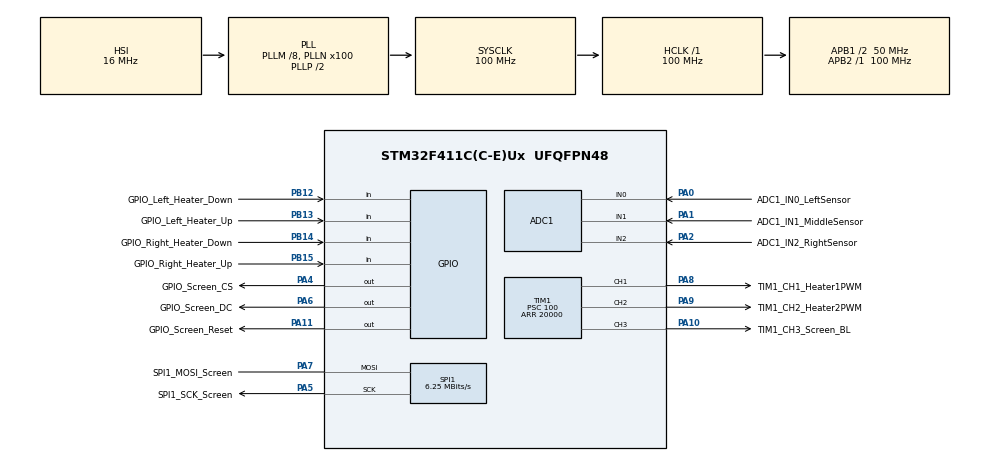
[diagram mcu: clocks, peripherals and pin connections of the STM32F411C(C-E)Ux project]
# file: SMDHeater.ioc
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ADC1.Channel-0\#ChannelRegularConversion=ADC_CHANNEL_0
ADC1.Channel-1\#ChannelRegularConversion=ADC_CHANNEL_1
ADC1.Channel-2\#ChannelRegularConversion=ADC_CHANNEL_2
ADC1.ContinuousConvMode=ENABLE
ADC1.DMAContinuousRequests=ENABLE
ADC1.NbrOfConversion=3
ADC1.NbrOfConversionFlag=1
ADC1.Rank-0\#ChannelRegularConversion=1
ADC1.Rank-1\#ChannelRegularConversion=2
ADC1.Rank-2\#ChannelRegularConversion=3
ADC1.SamplingTime-0\#ChannelRegularConversion=ADC_SAMPLETIME_84CYCLES
ADC1.SamplingTime-1\#ChannelRegularConversion=ADC_SAMPLETIME_84CYCLES
ADC1.SamplingTime-2\#ChannelRegularConversion=ADC_SAMPLETIME_84CYCLES
ADC1.master=1
Dma.ADC1.0.Direction=DMA_PERIPH_TO_MEMORY
Dma.ADC1.0.FIFOMode=DMA_FIFOMODE_DISABLE
Dma.ADC1.0.Instance=DMA2_Stream0
Dma.ADC1.0.MemDataAlignment=DMA_MDATAALIGN_WORD
Dma.ADC1.0.MemInc=DMA_MINC_ENABLE
Dma.ADC1.0.Mode=DMA_CIRCULAR
Dma.ADC1.0.PeriphDataAlignment=DMA_PDATAALIGN_WORD
Dma.ADC1.0.PeriphInc=DMA_PINC_DISABLE
Dma.ADC1.0.Priority=DMA_PRIORITY_LOW
Dma.Request0=ADC1
Mcu.Family=STM32F4
Mcu.Name=STM32F411C(C-E)Ux
Mcu.Package=UFQFPN48
NVIC.ADC_IRQn=true\:0\:0\:false\:false\:true\:true\:true\:true
NVIC.DMA2_Stream0_IRQn=true\:0\:0\:false\:false\:true\:false\:true\:true
NVIC.PriorityGroup=NVIC_PRIORITYGROUP_4
PA0-WKUP.GPIO_Label=ADC1_IN0_LeftSensor
PA0-WKUP.Signal=ADCx_IN0
PA1.GPIO_Label=ADC1_IN1_MiddleSensor
PA1.Signal=ADCx_IN1
PA10.GPIO_Label=TIM1_CH3_Screen_BL
PA10.Signal=S_TIM1_CH3
PA11.GPIO_Label=GPIO_Screen_Reset
PA11.Signal=GPIO_Output
PA13.Mode=Serial_Wire
PA13.Signal=SYS_JTMS-SWDIO
PA14.Mode=Serial_Wire
PA14.Signal=SYS_JTCK-SWCLK
PA2.GPIO_Label=ADC1_IN2_RightSensor
PA2.Signal=ADCx_IN2
PA4.GPIO_Label=GPIO_Screen_CS
PA4.Signal=GPIO_Output
PA5.GPIO_Label=SPI1_SCK_Screen
PA5.Mode=Simplex_Bidirectional_Master
PA5.Signal=SPI1_SCK
PA6.GPIO_Label=GPIO_Screen_DC
PA6.Signal=GPIO_Output
PA7.GPIO_Label=SPI1_MOSI_Screen
PA7.Mode=Simplex_Bidirectional_Master
PA7.Signal=SPI1_MOSI
PA8.GPIO_Label=TIM1_CH1_Heater1PWM
PA8.Signal=S_TIM1_CH1
PA9.GPIO_Label=TIM1_CH2_Heater2PWM
PA9.Signal=S_TIM1_CH2
PB12.GPIO_Label=GPIO_Left_Heater_Down
PB12.GPIO_PuPd=GPIO_PULLUP
PB12.Signal=GPIO_Input
PB13.GPIO_Label=GPIO_Left_Heater_Up
PB13.GPIO_PuPd=GPIO_PULLUP
PB13.Signal=GPIO_Input
PB14.GPIO_Label=GPIO_Right_Heater_Down
PB14.GPIO_PuPd=GPIO_PULLUP
PB14.Signal=GPIO_Input
PB15.GPIO_Label=GPIO_Right_Heater_Up
PB15.GPIO_PuPd=GPIO_PULLUP
PB15.Signal=GPIO_Input
PH0\ -\ OSC_IN.Mode=HSE-External-Oscillator
PH0\ -\ OSC_IN.Signal=RCC_OSC_IN
PH1\ -\ OSC_OUT.Mode=HSE-External-Oscillator
PH1\ -\ OSC_OUT.Signal=RCC_OSC_OUT
ProjectManager.HeapSize=0x200
ProjectManager.StackSize=0x400
ProjectManager.TargetToolchain=STM32CubeIDE
RCC.48MHZClocksFreq_Value=50000000
RCC.AHBFreq_Value=100000000
RCC.APB1CLKDivider=RCC_HCLK_DIV2
RCC.APB1Freq_Value=50000000
RCC.APB1TimFreq_Value=100000000
RCC.APB2Freq_Value=100000000
RCC.APB2TimFreq_Value=100000000
RCC.CortexFreq_Value=100000000
RCC.HCLKFreq_Value=100000000
RCC.HSE_VALUE=25000000
RCC.HSI_VALUE=16000000
RCC.LSE_VALUE=32768
RCC.PLLM=8
RCC.PLLN=100
RCC.SYSCLKFreq_VALUE=100000000
RCC.SYSCLKSource=RCC_SYSCLKSOURCE_PLLCLK
RCC.VCOOutputFreq_Value=200000000
SH.ADCx_IN0.0=ADC1_IN0,IN0
SH.ADCx_IN1.0=ADC1_IN1,IN1
SH.ADCx_IN2.0=ADC1_IN2,IN2
SH.S_TIM1_CH1.0=TIM1_CH1,PWM Generation1 CH1
SH.S_TIM1_CH2.0=TIM1_CH2,PWM Generation2 CH2
SH.S_TIM1_CH3.0=TIM1_CH3,PWM Generation3 CH3
SPI1.BaudRatePrescaler=SPI_BAUDRATEPRESCALER_16
SPI1.CalculateBaudRate=6.25 MBits/s
SPI1.Direction=SPI_DIRECTION_1LINE
SPI1.Mode=SPI_MODE_MASTER
SPI1.VirtualType=VM_MASTER
TIM1.AutoReloadPreload=TIM_AUTORELOAD_PRELOAD_ENABLE
TIM1.Channel-PWM\ Generation1\ CH1=TIM_CHANNEL_1
TIM1.Channel-PWM\ Generation2\ CH2=TIM_CHANNEL_2
TIM1.Channel-PWM\ Generation3\ CH3=TIM_CHANNEL_3
TIM1.Period=20000
TIM1.Prescaler=100
board=custom

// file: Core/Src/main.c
/* USER CODE BEGIN Header */
/**
  ******************************************************************************
  * @file           : main.c
  * @brief          : Main program body
  ******************************************************************************
  * @attention
  *
  * Copyright (c) 2023 STMicroelectronics.
  * All rights reserved.
  *
  * This software is licensed under terms that can be found in the LICENSE file
  * in the root directory of this software component.
  * If no LICENSE file comes with this software, it is provided AS-IS.
  *
  ******************************************************************************
  */
/* USER CODE END Header */
#include "main.h"
#include "adc.h"
#include "dma.h"
#include "spi.h"
#include "tim.h"
#include "gpio.h"

/* USER CODE BEGIN PV */
float versionID = 1.000;
float buildID = 1.020;

tCURSOR_DATA currentCursorPosition;
/* USER CODE END PV */

void SystemClock_Config(void);

int main(void)
{

  /* MCU Configuration--------------------------------------------------------*/

  /* Reset of all peripherals, Initializes the Flash interface and the Systick. */
  HAL_Init();

  /* Configure the system clock */
  SystemClock_Config();

  /* Initialize all configured peripherals */
  MX_GPIO_Init();
  MX_DMA_Init();
  MX_TIM1_Init();
  MX_SPI1_Init();
  MX_ADC1_Init();
  /* USER CODE BEGIN 2 */
  TIM1->CCR3 = 20000;
  screenInit();
  screenClear();
  renderCompleteFrame = true;
  HAL_ADC_Start_DMA(&hadc1, (uint32_t *)&thermistors, 3);
  /* USER CODE END 2 */

  /* Infinite loop */
  /* USER CODE BEGIN WHILE */
  while (1)
  {
	  checkButtons();
	  screenUpdate(false);
	  displayNextFrame();
	  HAL_ADC_Start_DMA(&hadc1, (uint32_t *)&thermistors, 3);
    /* USER CODE END WHILE */

  }
}

void SystemClock_Config(void)
{
  RCC_OscInitTypeDef RCC_OscInitStruct = {0};
  RCC_ClkInitTypeDef RCC_ClkInitStruct = {0};

  /** Configure the main internal regulator output voltage
  */
  __HAL_RCC_PWR_CLK_ENABLE();
  __HAL_PWR_VOLTAGESCALING_CONFIG(PWR_REGULATOR_VOLTAGE_SCALE1);

  /** Initializes the RCC Oscillators according to the specified parameters
  * in the RCC_OscInitTypeDef structure.
  */
  RCC_OscInitStruct.OscillatorType = RCC_OSCILLATORTYPE_HSI;
  RCC_OscInitStruct.HSIState = RCC_HSI_ON;
  RCC_OscInitStruct.HSICalibrationValue = RCC_HSICALIBRATION_DEFAULT;
  RCC_OscInitStruct.PLL.PLLState = RCC_PLL_ON;
  RCC_OscInitStruct.PLL.PLLSource = RCC_PLLSOURCE_HSI;
  RCC_OscInitStruct.PLL.PLLM = 8;
  RCC_OscInitStruct.PLL.PLLN = 100;
  RCC_OscInitStruct.PLL.PLLP = RCC_PLLP_DIV2;
  RCC_OscInitStruct.PLL.PLLQ = 4;
  if (HAL_RCC_OscConfig(&RCC_OscInitStruct) != HAL_OK)
  {
    Error_Handler();
  }

  /** Initializes the CPU, AHB and APB buses clocks
  */
  RCC_ClkInitStruct.ClockType = RCC_CLOCKTYPE_HCLK|RCC_CLOCKTYPE_SYSCLK
                              |RCC_CLOCKTYPE_PCLK1|RCC_CLOCKTYPE_PCLK2;
  RCC_ClkInitStruct.SYSCLKSource = RCC_SYSCLKSOURCE_PLLCLK;
  RCC_ClkInitStruct.AHBCLKDivider = RCC_SYSCLK_DIV1;
  RCC_ClkInitStruct.APB1CLKDivider = RCC_HCLK_DIV2;
  RCC_ClkInitStruct.APB2CLKDivider = RCC_HCLK_DIV1;

  if (HAL_RCC_ClockConfig(&RCC_ClkInitStruct, FLASH_LATENCY_3) != HAL_OK)
  {
    Error_Handler();
  }
}

void Error_Handler(void)
{
  __disable_irq();
  while (1)
  {
  }
}
